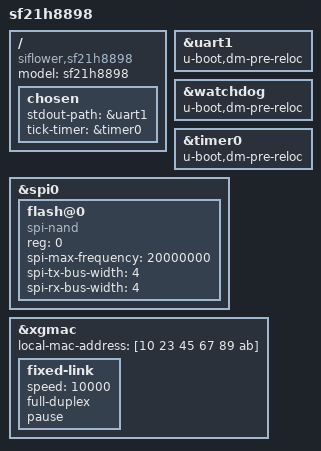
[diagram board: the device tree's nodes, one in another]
// SPDX-License-Identifier: GPL-2.0

/dts-v1/;
#include "sf21h8898.dtsi"

/ {
	model = "sf21h8898";
	compatible = "siflower,sf21h8898";

	chosen {
		stdout-path = &uart1;
		tick-timer = &timer0;
	};

};

&uart1 {
	u-boot,dm-pre-reloc;
};

&watchdog {
	u-boot,dm-pre-reloc;
};

&timer0 {
	u-boot,dm-pre-reloc;
};

&spi0 {
	status = "okay";

	flash@0 {
		compatible = "spi-nand";
		reg = <0>;
		spi-max-frequency = <20000000>;
		spi-tx-bus-width = <4>;
		spi-rx-bus-width = <4>;
		#address-cells = <1>;
		#size-cells = <1>;
	};
};


&xgmac {
	status = "okay";
	local-mac-address = [10 23 45 67 89 ab];

	fixed-link {
		speed = <10000>;
		full-duplex;
		pause;
	};
};
